VERSION ""

NS_ :

BS_:

BU_: Vector__XXX

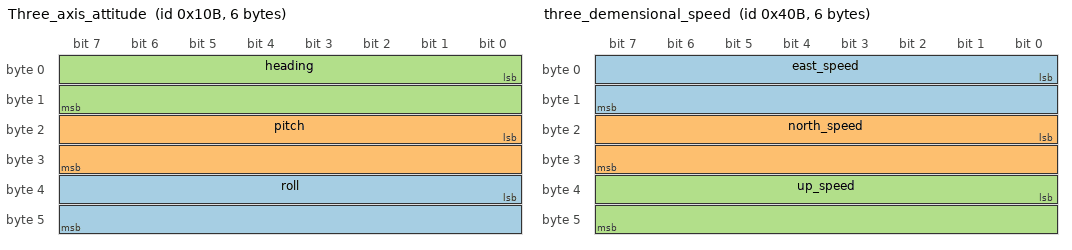
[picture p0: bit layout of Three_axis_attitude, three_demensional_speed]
BO_ 267 Three_axis_attitude: 6 Vector__XXX
SG_ roll : 32|16@1- (0.01,0) [-180|180] "бу" Vector__XXX
SG_ pitch : 16|16@1- (0.01,0) [-90|90] "бу" Vector__XXX
SG_ heading : 0|16@1+ (0.01,0) [0|360] "бу" Vector__XXX

BO_ 523 lon_and_lat: 8 Vector__XXX
SG_ lat : 0|32@1- (1E-007,0) [-90|90] "бу" Vector__XXX
SG_ lon : 32|32@1- (1E-007,0) [-180|180] "бу" Vector__XXX

BO_ 779 alt_and_flag: 5 Vector__XXX
SG_ alt : 0|32@1- (0.001,0) [-2147483.648|2147483.647] "m" Vector__XXX
SG_ nav_flag : 32|8@1+ (1,0) [0|255] "" Vector__XXX

BO_ 1035 three_demensional_speed: 6 Vector__XXX
SG_ east_speed : 0|16@1- (0.01,0) [-327.68|327.67] "m/s" Vector__XXX
SG_ north_speed : 16|16@1- (0.01,0) [-327.68|327.67] "m/s" Vector__XXX
SG_ up_speed : 32|16@1- (0.01,0) [-323.68|327.67] "m/s" Vector__XXX

BO_ 1291 xy_acc: 8 Vector__XXX
SG_ x_acc : 0|32@1- (1E-005,0) [-160|160] "m/s2" Vector__XXX
SG_ y_acc : 32|32@1- (1E-005,0) [-160|160] "m/s2" Vector__XXX

BO_ 1547 xy_gyro: 8 Vector__XXX
SG_ x_gyro : 0|32@1- (1E-005,0) [-300|300] "deg/s" Vector__XXX
SG_ y_gyro : 32|32@1- (1E-005,0) [-300|300] "deg/s" Vector__XXX

BO_ 1803 z_acc_gyro: 8 Vector__XXX
SG_ z_gyro : 0|32@1- (1E-005,0) [-300|300] "deg/s" Vector__XXX
SG_ z_acc : 32|32@1- (1E-005,0) [-160|160] "m/s2" Vector__XXX

BO_ 155 GPS_time: 6 Vector__XXX
SG_ gps_week : 0|16@1+ (1,0) [0|65535] "" Vector__XXX
SG_ gps_ms : 16|32@1+ (1,0) [0|4294967295] "ms" Vector__XXX

BO_ 539 gps_lat_lon: 8 Vector__XXX
SG_ lat : 0|32@1- (1E-007,0) [-90|90] "бу" Vector__XXX
SG_ lon : 32|32@1- (1E-007,0) [-180|180] "бу" Vector__XXX

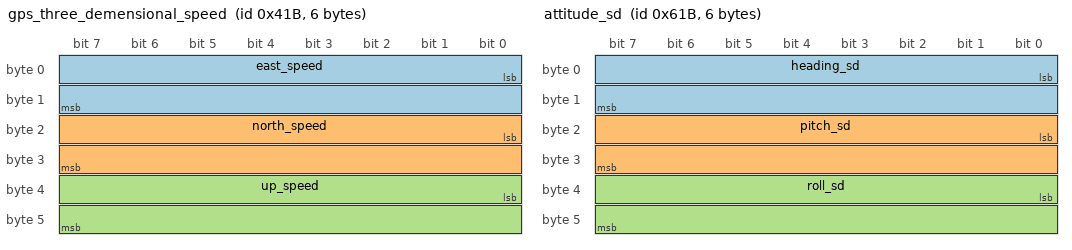
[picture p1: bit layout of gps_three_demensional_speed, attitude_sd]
BO_ 1051 gps_three_demensional_speed: 6 Vector__XXX
SG_ east_speed : 0|16@1- (0.01,0) [-327.68|327.67] "m/s" Vector__XXX
SG_ north_speed : 16|16@1- (0.01,0) [-325.68|327.67] "m/s" Vector__XXX
SG_ up_speed : 32|16@1- (0.01,0) [-323.68|327.67] "m/s" Vector__XXX

BO_ 795 gps_alt_flag: 5 Vector__XXX
SG_ alt : 0|32@1- (0.001,0) [-1000|8000] "m" Vector__XXX
SG_ nav_flag : 32|8@1+ (1,0) [0|255] "" Vector__XXX

BO_ 1307 gps_three_axis_attitude: 4 Vector__XXX
SG_ heading : 0|16@1+ (0.01,0) [0|655.35] "бу" Vector__XXX
SG_ pitch : 16|16@1- (0.01,0) [-90|90] "бу" Vector__XXX

BO_ 1563 attitude_sd: 6 Vector__XXX
SG_ heading_sd : 0|16@1+ (0.01,0) [0|360] "бу" Vector__XXX
SG_ pitch_sd : 16|16@1- (0.01,0) [-327.68|327.67] "бу" Vector__XXX
SG_ roll_sd : 32|16@1- (0.01,0) [-327.68|327.67] "бу" Vector__XXX

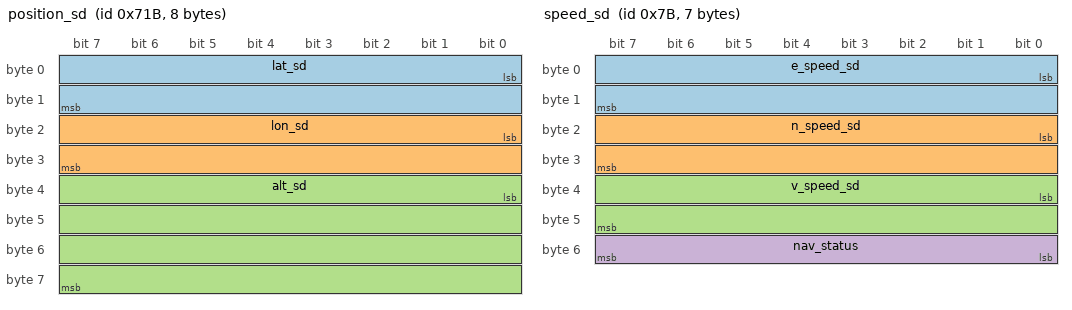
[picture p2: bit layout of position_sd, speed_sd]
BO_ 1819 position_sd: 8 Vector__XXX
SG_ lat_sd : 0|16@1- (0.01,0) [-327.68|327.67] "бу" Vector__XXX
SG_ lon_sd : 16|16@1- (0.01,0) [-327.68|327.67] "бу" Vector__XXX
SG_ alt_sd : 32|32@1- (0.001,0) [-2147483.648|2147483.647] "m" Vector__XXX

BO_ 123 speed_sd: 7 Vector__XXX
SG_ e_speed_sd : 0|16@1- (0.01,0) [-327.68|327.67] "m/s" Vector__XXX
SG_ n_speed_sd : 16|16@1- (0.01,0) [-327.68|327.67] "m/s" Vector__XXX
SG_ v_speed_sd : 32|16@1- (0.01,0) [-327.68|327.67] "m/s" Vector__XXX
SG_ nav_status : 48|8@1+ (1,0) [0|255] "" Vector__XXX

BA_DEF_  "BusType" STRING ;
BA_DEF_ SG_  "GenSigStartValue" FLOAT -3.4E+038 3.4E+038;

BA_DEF_DEF_  "BusType" "CAN";
BA_DEF_DEF_  "GenSigStartValue" 0;

BA_ "GenSigStartValue" SG_ 267 roll 400;

VAL_ 779 nav_flag 1 "single" 2 "deferential" 4 "RTK_fix" 5 "RTK_float" 6 "SBAS" ;
VAL_ 795 nav_flag 0 "invalid" 1 "single" 2 "deferential" 5 "float" 4 "narrow_int" 7 "other_fix" ;
VAL_ 123 nav_status 1 "align" 3 "nav" ;
